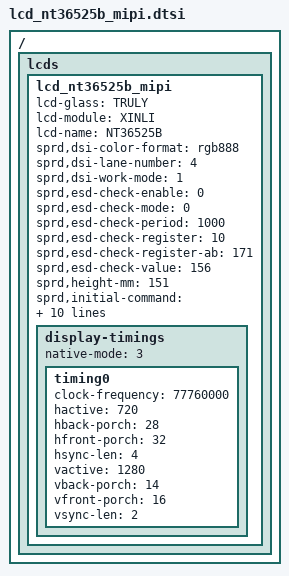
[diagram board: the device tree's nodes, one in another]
/ {
    fragment {
        target-path = "/";
        __overlay__ {
            lcds {
                lcd_nt36525b_mipi: lcd_nt36525b_mipi {
                    lcd-glass = "TRULY";
                    lcd-module = "XINLI";
                    lcd-name = "NT36525B";
                    sprd,dsi-color-format = "rgb888";
                    sprd,dsi-lane-number = <4>;
                    sprd,dsi-work-mode = <1>;
                    sprd,esd-check-enable = <0>;
                    sprd,esd-check-mode = <0>;
                    sprd,esd-check-period = <1000>;
                    sprd,esd-check-register = <10>;
                    sprd,esd-check-register-ab = <171>;
                    sprd,esd-check-value = <156>;
                    sprd,height-mm = <151>;
                    sprd,initial-command = <
                        0x23000002 0xff202300 0x2fb01 0x23000002 0x1552300 0x20355 0x23000002
                        0x5b12300 0x20769 0x23000002 0x8b72300 0x20e87 0x23000002 0xf552300
                        0x21f01 0x23000002 0x69912300 0x26d33 0x23000002 0x88002300 0x294c0
                        0x23000002 0x95092300 0x29609 0x23000002 0xff232300 0x2fb01 0x23000002
                        0x12b42300 0x215e9 0x23000002 0x160b2300 0x2ff24 0x23000002 0xfb012300
                        0x20005 0x23000002 0x11f2300 0x20200 0x23000002 0x3002300 0x2041e 0x23000002
                        0x5002300 0x20600 0x23000002 0x7132300 0x2080f 0x23000002 0x9122300 0x20a0e
                        0x23000002 0xb112300 0x20c0d 0x23000002 0xd102300 0x20e0c 0x23000002 0xf042300
                        0x21004 0x23000002 0x11002300 0x21200 0x23000002 0x13002300 0x21400 0x23000002
                        0x15002300 0x21605 0x23000002 0x171f2300 0x21800 0x23000002 0x19002300 0x21a1e
                        0x23000002 0x1b002300 0x21c00 0x23000002 0x1d132300 0x21e0f 0x23000002 0x1f122300
                        0x2200e 0x23000002 0x21112300 0x2220d 0x23000002 0x23102300 0x2240c 0x23000002
                        0x25042300 0x22604 0x23000002 0x27002300 0x22800 0x23000002 0x29002300 0x22a00
                        0x23000002 0x2b002300 0x22f06 0x23000002 0x30442300 0x23100 0x23000002 0x32002300
                        0x23344 0x23000002 0x34062300 0x23500 0x23000002 0x36002300 0x23744 0x23000002
                        0x38442300 0x23900 0x23000002 0x3a962300 0x23b94 0x23000002 0x3d922300 0x24d12
                        0x23000002 0x4e342300 0x24f56 0x23000002 0x50782300 0x25187 0x23000002 0x52652300
                        0x25343 0x23000002 0x54212300 0x25583 0x23000002 0x56482300 0x25821 0x23000002
                        0x59002300 0x25a84 0x23000002 0x5b822300 0x25c9f 0x23000002 0x5d022300 0x25e10
                        0x23000002 0x5f002300 0x26080 0x23000002 0x61902300 0x26410 0x23000002 0x80082300
                        0x28104 0x23000002 0x82082300 0x28304 0x23000002 0x84002300 0x28501 0x23000002
                        0x86042300 0x2882f 0x23000002 0x89402300 0x28a90 0x23000002 0x8d802300 0x28e10
                        0x23000002 0x91402300 0x292a6 0x23000002 0x93102300 0x29410 0x23000002 0xab002300
                        0x2ad00 0x23000002 0xaf042300 0x2b005 0x23000002 0xb1a22300 0x2ff25 0x23000002
                        0xfb012300 0x20a82 0x23000002 0xb742300 0x20c01 0x23000002 0x17822300 0x21806
                        0x23000002 0x190f2300 0x21e00 0x23000002 0x1f842300 0x22082 0x23000002 0x23052300
                        0x224a2 0x23000002 0x25002300 0x22684 0x23000002 0x27822300 0x22a05 0x23000002
                        0x2ba22300 0x22f55 0x23000002 0x30112300 0x23100 0x23000002 0x32002300 0x2337b
                        0x23000002 0x34942300 0x23705 0x23000002 0x38a22300 0x24011 0x23000002 0x41002300
                        0x24284 0x23000002 0x43822300 0x24605 0x23000002 0x47a22300 0x24900 0x23000002
                        0x4a002300 0x24b96 0x23000002 0x4c942300 0x24fae 0x23000002 0x50982300 0x25305
                        0x23000002 0x54a22300 0x25520 0x23000002 0x56a42300 0x25a80 0x23000002 0x5bc02300
                        0x25c00 0x23000002 0x5d962300 0x25e94 0x23000002 0x61842300 0x26282 0x23000002
                        0x65052300 0x266a2 0x23000002 0x8a002300 0x2ca1c 0x23000002 0xcc1c2300 0x2cd00
                        0x23000002 0xce002300 0x2d311 0x23000002 0xd4cc2300 0x2d511 0x23000002 0xff262300
                        0x2fb01 0x23000002 0xa12300 0x2044b 0x23000002 0x6ff2300 0x20c0b 0x23000002 0xd012300
                        0x20e02 0x23000002 0xf062300 0x21007 0x23000002 0x11002300 0x2131a 0x23000002 0x148e2300
                        0x21681 0x23000002 0x191a2300 0x21a0d 0x23000002 0x1b122300 0x21c82 0x23000002 0x1d002300
                        0x21ea6 0x23000002 0x1fa62300 0x22400 0x23000002 0x25b22300 0x22666 0x23000002 0x27662300
                        0x22866 0x23000002 0x29062300 0x22f02 0x23000002 0x30a62300 0x23111 0x23000002 0x32112300
                        0x23403 0x23000002 0x35a62300 0x23678 0x23000002 0x37662300 0x23866 0x23000002 0x39062300
                        0x23f10 0x23000002 0x40a42300 0x24100 0x23000002 0x42002300 0x24300 0x23000002 0x44122300
                        0x2450e 0x23000002 0x58c92300 0x259c9 0x23000002 0x5ac92300 0x25bc9 0x23000002 0x5c002300
                        0x25d00 0x23000002 0x5e102300 0x25f00 0x23000002 0x60002300 0x26100 0x23000002 0x63962300
                        0x26494 0x23000002 0x67842300 0x26882 0x23000002 0x6b002300 0x26c05 0x23000002 0x6d002300
                        0x27005 0x23000002 0x71c62300 0x27384 0x23000002 0x74822300 0x27705 0x23000002 0x78c62300
                        0x27900 0x23000002 0x7a842300 0x27b82 0x23000002 0x7e052300 0x27fc6 0x23000002 0x80002300
                        0x28100 0x23000002 0x82962300 0x28394 0x23000002 0x86842300 0x28782 0x23000002 0x8a052300
                        0x28bc6 0x23000002 0x8c002300 0x28d00 0x23000002 0x8e012300 0x28f00 0x23000002 0x90002300
                        0x29100 0x23000002 0x92062300 0x29340 0x23000002 0x94002300 0x29500 0x23000002 0x96002300
                        0x2990d 0x23000002 0x9a362300 0x29b0c 0x23000002 0x9c9e2300 0x2a91c 0x23000002 0xaa3e2300
                        0x2ab2a 0x23000002 0xac542300 0x2ad22 0x23000002 0xae262300 0x2af34 0x23000002 0xb0362300
                        0x2b14c 0x23000002 0xb2462300 0x2b32c 0x23000002 0xb4442300 0x2b53c 0x23000002 0xb62e2300
                        0x2b756 0x23000002 0xb84e2300 0x2b924 0x23000002 0xff272300 0x2fb01 0x23000002 0x13002300
                        0x21455 0x23000002 0x1f552300 0x2ff10 0x23000002 0xfb012300 0x2ba03 0x23000002 0xff202300
                        0x2fb01 0x23000002 0xff102300 0x2fb01 0x23780001 0x11233200 0x1292300 0x23500
                    >;
                    sprd,is_ic_nt36525b = <1>;
                    sprd,phy-bit-clock = <5900000>;
                    sprd,phy-escape-clock = <20000>;
                    sprd,reset-on-sequence = <1 10 0 10 1 20>;
                    sprd,sleep-in-command = [23 32 00 01 28 23 78 00 01 10];
                    sprd,sleep-out-command = [23 78 00 01 11 23 32 00 01 29];
                    sprd,width-mm = <68>;

                    display-timings {
                        native-mode = <3>;

                        timing0 {
                            clock-frequency = <77760000>;
                            hactive = <720>;
                            hback-porch = <28>;
                            hfront-porch = <32>;
                            hsync-len = <4>;
                            vactive = <1280>;
                            vback-porch = <14>;
                            vfront-porch = <16>;
                            vsync-len = <2>;
                        };
                    };
                };
            };
        };
    };
};

